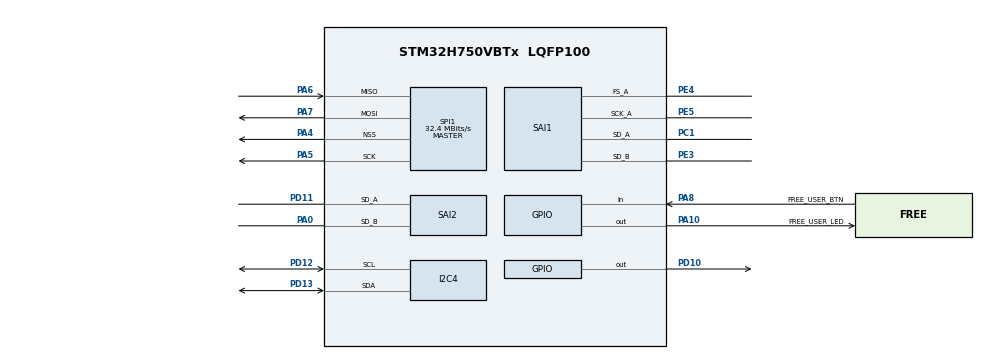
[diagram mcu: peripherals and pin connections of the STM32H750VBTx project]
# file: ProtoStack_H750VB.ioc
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CORTEX_M7.CPU_DCache=Disabled
CORTEX_M7.CPU_ICache=Enabled
CORTEX_M7.Enable-Cortex_Memory_Protection_Unit_Region0_Settings=__NULL
CORTEX_M7.Enable-Cortex_Memory_Protection_Unit_Region1_Settings=__NULL
CORTEX_M7.Enable-Cortex_Memory_Protection_Unit_Region2_Settings=__NULL
CORTEX_M7.MPU_Control=MPU_PRIVILEGED_DEFAULT
Dma.Request0=SAI1_A
Dma.Request1=SAI1_B
Dma.Request2=SAI2_A
Dma.Request3=SAI2_B
Dma.Request4=SPI1_RX
Dma.Request5=SPI1_TX
Dma.SAI1_A.0.Direction=DMA_PERIPH_TO_MEMORY
Dma.SAI1_A.0.EventEnable=DISABLE
Dma.SAI1_A.0.FIFOMode=DMA_FIFOMODE_DISABLE
Dma.SAI1_A.0.Instance=DMA1_Stream0
Dma.SAI1_A.0.MemDataAlignment=DMA_MDATAALIGN_HALFWORD
Dma.SAI1_A.0.MemInc=DMA_MINC_ENABLE
Dma.SAI1_A.0.Mode=DMA_CIRCULAR
Dma.SAI1_A.0.PeriphDataAlignment=DMA_PDATAALIGN_HALFWORD
Dma.SAI1_A.0.PeriphInc=DMA_PINC_DISABLE
Dma.SAI1_A.0.Polarity=HAL_DMAMUX_REQ_GEN_RISING
Dma.SAI1_A.0.Priority=DMA_PRIORITY_HIGH
Dma.SAI1_A.0.RequestNumber=1
Dma.SAI1_A.0.SignalID=NONE
Dma.SAI1_A.0.SyncEnable=DISABLE
Dma.SAI1_A.0.SyncPolarity=HAL_DMAMUX_SYNC_NO_EVENT
Dma.SAI1_A.0.SyncRequestNumber=1
Dma.SAI1_A.0.SyncSignalID=NONE
Dma.SAI1_B.1.Direction=DMA_MEMORY_TO_PERIPH
Dma.SAI1_B.1.EventEnable=DISABLE
Dma.SAI1_B.1.FIFOMode=DMA_FIFOMODE_DISABLE
Dma.SAI1_B.1.Instance=DMA1_Stream1
Dma.SAI1_B.1.MemDataAlignment=DMA_MDATAALIGN_HALFWORD
Dma.SAI1_B.1.MemInc=DMA_MINC_ENABLE
Dma.SAI1_B.1.Mode=DMA_CIRCULAR
Dma.SAI1_B.1.PeriphDataAlignment=DMA_PDATAALIGN_HALFWORD
Dma.SAI1_B.1.PeriphInc=DMA_PINC_DISABLE
Dma.SAI1_B.1.Polarity=HAL_DMAMUX_REQ_GEN_RISING
Dma.SAI1_B.1.Priority=DMA_PRIORITY_HIGH
Dma.SAI1_B.1.RequestNumber=1
Dma.SAI1_B.1.SignalID=NONE
Dma.SAI1_B.1.SyncEnable=DISABLE
Dma.SAI1_B.1.SyncPolarity=HAL_DMAMUX_SYNC_NO_EVENT
Dma.SAI1_B.1.SyncRequestNumber=1
Dma.SAI1_B.1.SyncSignalID=NONE
Dma.SAI2_A.2.Direction=DMA_PERIPH_TO_MEMORY
Dma.SAI2_A.2.EventEnable=DISABLE
Dma.SAI2_A.2.FIFOMode=DMA_FIFOMODE_DISABLE
Dma.SAI2_A.2.Instance=DMA1_Stream2
Dma.SAI2_A.2.MemDataAlignment=DMA_MDATAALIGN_HALFWORD
Dma.SAI2_A.2.MemInc=DMA_MINC_ENABLE
Dma.SAI2_A.2.Mode=DMA_CIRCULAR
Dma.SAI2_A.2.PeriphDataAlignment=DMA_PDATAALIGN_HALFWORD
Dma.SAI2_A.2.PeriphInc=DMA_PINC_DISABLE
Dma.SAI2_A.2.Polarity=HAL_DMAMUX_REQ_GEN_RISING
Dma.SAI2_A.2.Priority=DMA_PRIORITY_MEDIUM
Dma.SAI2_A.2.RequestNumber=1
Dma.SAI2_A.2.SignalID=NONE
Dma.SAI2_A.2.SyncEnable=DISABLE
Dma.SAI2_A.2.SyncPolarity=HAL_DMAMUX_SYNC_NO_EVENT
Dma.SAI2_A.2.SyncRequestNumber=1
Dma.SAI2_A.2.SyncSignalID=NONE
Dma.SAI2_B.3.Direction=DMA_MEMORY_TO_PERIPH
Dma.SAI2_B.3.EventEnable=DISABLE
Dma.SAI2_B.3.FIFOMode=DMA_FIFOMODE_DISABLE
Dma.SAI2_B.3.Instance=DMA1_Stream3
Dma.SAI2_B.3.MemDataAlignment=DMA_MDATAALIGN_HALFWORD
Dma.SAI2_B.3.MemInc=DMA_MINC_ENABLE
Dma.SAI2_B.3.Mode=DMA_CIRCULAR
Dma.SAI2_B.3.PeriphDataAlignment=DMA_PDATAALIGN_HALFWORD
Dma.SAI2_B.3.PeriphInc=DMA_PINC_DISABLE
Dma.SAI2_B.3.Polarity=HAL_DMAMUX_REQ_GEN_RISING
Dma.SAI2_B.3.Priority=DMA_PRIORITY_MEDIUM
Dma.SAI2_B.3.RequestNumber=1
Dma.SAI2_B.3.SignalID=NONE
Dma.SAI2_B.3.SyncEnable=DISABLE
Dma.SAI2_B.3.SyncPolarity=HAL_DMAMUX_SYNC_NO_EVENT
Dma.SAI2_B.3.SyncRequestNumber=1
Dma.SAI2_B.3.SyncSignalID=NONE
Dma.SPI1_RX.4.Direction=DMA_PERIPH_TO_MEMORY
Dma.SPI1_RX.4.EventEnable=DISABLE
Dma.SPI1_RX.4.FIFOMode=DMA_FIFOMODE_DISABLE
Dma.SPI1_RX.4.Instance=DMA1_Stream4
Dma.SPI1_RX.4.MemDataAlignment=DMA_MDATAALIGN_BYTE
Dma.SPI1_RX.4.MemInc=DMA_MINC_ENABLE
Dma.SPI1_RX.4.Mode=DMA_NORMAL
Dma.SPI1_RX.4.PeriphDataAlignment=DMA_PDATAALIGN_BYTE
Dma.SPI1_RX.4.PeriphInc=DMA_PINC_DISABLE
Dma.SPI1_RX.4.Polarity=HAL_DMAMUX_REQ_GEN_RISING
Dma.SPI1_RX.4.Priority=DMA_PRIORITY_LOW
Dma.SPI1_RX.4.RequestNumber=1
Dma.SPI1_RX.4.SignalID=NONE
Dma.SPI1_RX.4.SyncEnable=DISABLE
Dma.SPI1_RX.4.SyncPolarity=HAL_DMAMUX_SYNC_NO_EVENT
Dma.SPI1_RX.4.SyncRequestNumber=1
Dma.SPI1_RX.4.SyncSignalID=NONE
Dma.SPI1_TX.5.Direction=DMA_MEMORY_TO_PERIPH
Dma.SPI1_TX.5.EventEnable=DISABLE
Dma.SPI1_TX.5.FIFOMode=DMA_FIFOMODE_DISABLE
Dma.SPI1_TX.5.Instance=DMA1_Stream5
Dma.SPI1_TX.5.MemDataAlignment=DMA_MDATAALIGN_BYTE
Dma.SPI1_TX.5.MemInc=DMA_MINC_ENABLE
Dma.SPI1_TX.5.Mode=DMA_NORMAL
Dma.SPI1_TX.5.PeriphDataAlignment=DMA_PDATAALIGN_BYTE
Dma.SPI1_TX.5.PeriphInc=DMA_PINC_DISABLE
Dma.SPI1_TX.5.Polarity=HAL_DMAMUX_REQ_GEN_RISING
Dma.SPI1_TX.5.Priority=DMA_PRIORITY_LOW
Dma.SPI1_TX.5.RequestNumber=1
Dma.SPI1_TX.5.SignalID=NONE
Dma.SPI1_TX.5.SyncEnable=DISABLE
Dma.SPI1_TX.5.SyncPolarity=HAL_DMAMUX_SYNC_NO_EVENT
Dma.SPI1_TX.5.SyncRequestNumber=1
Dma.SPI1_TX.5.SyncSignalID=NONE
I2C4.Timing=0x307075B1
Mcu.Family=STM32H7
Mcu.Name=STM32H750VBTx
Mcu.Package=LQFP100
NVIC.DMA1_Stream0_IRQn=true\:0\:0\:false\:false\:true\:false\:true\:true
NVIC.DMA1_Stream1_IRQn=true\:0\:0\:false\:false\:true\:false\:true\:true
NVIC.DMA1_Stream2_IRQn=true\:0\:0\:false\:false\:true\:false\:true\:true
NVIC.DMA1_Stream3_IRQn=true\:0\:0\:false\:false\:true\:false\:true\:true
NVIC.DMA1_Stream4_IRQn=true\:0\:0\:false\:false\:true\:false\:true\:true
NVIC.DMA1_Stream5_IRQn=true\:0\:0\:false\:false\:true\:false\:true\:true
NVIC.PriorityGroup=NVIC_PRIORITYGROUP_4
NVIC.SAI1_IRQn=true\:0\:0\:false\:false\:true\:true\:true\:true
NVIC.SAI2_IRQn=true\:0\:0\:false\:false\:true\:true\:true\:true
NVIC.SPI1_IRQn=true\:0\:0\:false\:false\:true\:true\:true\:true
NVIC.TIM2_IRQn=true\:0\:0\:false\:false\:true\:true\:true\:true
PA0.Mode=SAI_B_SyncSlave
PA0.Signal=SAI2_SD_B
PA10.GPIO_Label=FREE_USER_LED
PA10.PinState=GPIO_PIN_SET
PA10.Signal=GPIO_Output
PA13\ (JTMS/SWDIO).Mode=Serial_Wire
PA13\ (JTMS/SWDIO).PinAttribute=Free
PA13\ (JTMS/SWDIO).Signal=DEBUG_JTMS-SWDIO
PA14\ (JTCK/SWCLK).Mode=Serial_Wire
PA14\ (JTCK/SWCLK).PinAttribute=Free
PA14\ (JTCK/SWCLK).Signal=DEBUG_JTCK-SWCLK
PA4.GPIO_PuPd=GPIO_PULLUP
PA4.GPIO_Speed=GPIO_SPEED_FREQ_VERY_HIGH
PA4.Mode=NSS_Signal_Hard_Output
PA4.Signal=SPI1_NSS
PA5.GPIO_Speed=GPIO_SPEED_FREQ_VERY_HIGH
PA5.Mode=Full_Duplex_Master
PA5.Signal=SPI1_SCK
PA6.GPIO_Speed=GPIO_SPEED_FREQ_VERY_HIGH
PA6.Mode=Full_Duplex_Master
PA6.Signal=SPI1_MISO
PA7.GPIO_Speed=GPIO_SPEED_FREQ_VERY_HIGH
PA7.Mode=Full_Duplex_Master
PA7.Signal=SPI1_MOSI
PA8.GPIO_Label=FREE_USER_BTN
PA8.PinAttribute=Free
PA8.Signal=GPIO_Input
PC1.Mode=SAI_A_AsyncSlave
PC1.PinAttribute=Free
PC1.Signal=SAI1_SD_A
PD10.Signal=GPIO_Output
PD11.Mode=SAI_A_SyncSlave
PD11.Signal=SAI2_SD_A
PD12.Mode=I2C
PD12.Signal=I2C4_SCL
PD13.Mode=I2C
PD13.Signal=I2C4_SDA
PE3.Mode=SAI_B_SyncSlave
PE3.PinAttribute=Free
PE3.Signal=SAI1_SD_B
PE4.Mode=SAI_A_AsyncSlave
PE4.Signal=SAI1_FS_A
PE5.GPIO_Speed=GPIO_SPEED_FREQ_LOW
PE5.Mode=SAI_A_AsyncSlave
PE5.Signal=SAI1_SCK_A
PH0-OSC_IN\ (PH0).Mode=HSE-External-Oscillator
PH0-OSC_IN\ (PH0).PinAttribute=Free
PH0-OSC_IN\ (PH0).Signal=RCC_OSC_IN
PH1-OSC_OUT\ (PH1).Mode=HSE-External-Oscillator
PH1-OSC_OUT\ (PH1).PinAttribute=Free
PH1-OSC_OUT\ (PH1).Signal=RCC_OSC_OUT
ProjectManager.HeapSize=0x200
ProjectManager.StackSize=0x400
ProjectManager.TargetToolchain=STM32CubeIDE
RCC.ADCCLockSelection=RCC_ADCCLKSOURCE_PLL2
RCC.ADCFreq_Value=129600000
RCC.APB1Freq_Value=120000000
RCC.APB2Freq_Value=120000000
RCC.APB3Freq_Value=120000000
RCC.APB4Freq_Value=120000000
RCC.CECCLockSelection=RCC_CECCLKSOURCE_LSI
RCC.CKPERSourceSelection=RCC_CLKPSOURCE_HSI
RCC.CSI_VALUE=4000000
RCC.CortexFreq_Value=60000000
RCC.Cortex_Div=SYSTICK_CLKSOURCE_HCLK_DIV8
RCC.Cortex_DivARG=SystemCoreClock/1000
RCC.D1PPRE=RCC_APB3_DIV2
RCC.D2PPRE1=RCC_APB1_DIV2
RCC.D2PPRE2=RCC_APB2_DIV2
RCC.D3PPRE=RCC_APB4_DIV2
RCC.DFSDMCLockSelection=RCC_DFSDM1CLKSOURCE_D2PCLK1
RCC.DIVM1=4
RCC.DIVM2=4
RCC.DIVM3=10
RCC.DIVN1=160
RCC.DIVN2=108
RCC.DIVN3=128
RCC.DIVP2=5
RCC.DIVP3=25
RCC.DIVQ1=20
RCC.DIVQ2=2
RCC.DIVQ3=16
RCC.DIVR1=10
RCC.DIVR2=3
RCC.DSICLockSelection=RCC_DSICLKSOURCE_PHY
RCC.DSIPHY_Div=8
RCC.DSITX_Div=4
RCC.DSI_PHY_VALUE=12288000
RCC.EXTERNAL_CLOCK_VALUE=12288000
RCC.EnbaleCSS=true
RCC.FDCANCLockSelection=RCC_FDCANCLKSOURCE_PLL
RCC.HCLKFreq_Value=240000000
RCC.HPRE=RCC_HCLK_DIV2
RCC.HSE_VALUE=24000000
RCC.HSIDiv=RCC_PLLSAIDIVR_4
RCC.HSI_VALUE=64000000
RCC.I2C123CLockSelection=RCC_I2C123CLKSOURCE_D2PCLK1
RCC.I2C4CLockSelection=RCC_I2C4CLKSOURCE_D3PCLK1
RCC.LPTIM1CLockSelection=RCC_LPTIM1CLKSOURCE_D2PCLK1
RCC.LPTIM2CLockSelection=RCC_LPTIM2CLKSOURCE_D3PCLK1
RCC.LPTIM345CLockSelection=RCC_LPTIM345CLKSOURCE_D3PCLK1
RCC.LPUART1CLockSelection=RCC_LPUART1CLKSOURCE_D3PCLK1
RCC.LSEState=RCC_LSE_OFF
RCC.LSE_VALUE=32768
RCC.PLL1_VCI_Range-AdvancedSettings=RCC_PLL1VCIRANGE_0
RCC.PLLDSIDev=2
RCC.PLLDSIIDF=DSI_PLL_IN_DIV1
RCC.PLLDSIMult=2
RCC.PLLDSINDIV=20
RCC.PLLDSIODF=DSI_PLL_OUT_DIV1
RCC.PLLFRACN=0
RCC.PLLSourceVirtual=RCC_PLLSOURCE_HSE
RCC.QSPICLockSelection=RCC_QSPICLKSOURCE_PLL2
RCC.RC48_VALUE=48000000
RCC.RCC_MCO1Source=RCC_MCO1SOURCE_HSI
RCC.RCC_MCO2Source=RCC_MCO2SOURCE_SYSCLK
RCC.RCC_MCODiv1=RCC_MCODIV_1
RCC.RCC_MCODiv2=RCC_MCODIV_1
RCC.RCC_RTC_Clock_Source_FROM_HSE=RCC_RTCCLKSOURCE_HSE_DIV2
RCC.RNGCLockSelection=RCC_RNGCLKSOURCE_HSI48
RCC.SAI1CLockSelection=RCC_SAI1CLKSOURCE_PLL3
RCC.SAI23CLockSelection=RCC_SAI23CLKSOURCE_PLL3
RCC.SAI4ACLockSelection=RCC_SAI4ACLKSOURCE_PLL
RCC.SAI4BCLockSelection=RCC_SAI4BCLKSOURCE_PLL
RCC.SPDIFCLockSelection=RCC_SPDIFRXCLKSOURCE_PLL
RCC.SPI123CLockSelection=RCC_SPI123CLKSOURCE_PLL2
RCC.SPI6CLockSelection=RCC_SPI6CLKSOURCE_PLL3
RCC.SWPCLockSelection=RCC_SWPMI1CLKSOURCE_D2PCLK1
RCC.SYSCLKFreq_VALUE=480000000
RCC.SYSCLKSource=RCC_SYSCLKSOURCE_PLLCLK
RCC.Spi45ClockSelection=RCC_SPI45CLKSOURCE_D2PCLK1
RCC.USART16CLockSelection=RCC_USART16CLKSOURCE_D2PCLK2
RCC.USART234578CLockSelection=RCC_USART234578CLKSOURCE_D2PCLK1
RCC.USBCLockSelection=RCC_USBCLKSOURCE_HSI48
RCC.USBFreq_Value=48000000
SAI1.AudioMode-SAI_B_SyncSlave=SAI_MODESLAVE_TX
SAI1.BasicDataSize-SAI_A_AsyncSlave=SAI_PROTOCOL_DATASIZE_16BITEXTENDED
SAI1.BasicDataSize-SAI_B_SyncSlave=SAI_PROTOCOL_DATASIZE_16BITEXTENDED
SAI1.FIFOThreshold-SAI_B_SyncSlave=SAI_FIFOTHRESHOLD_EMPTY
SAI1.InitProtocol-SAI_A_AsyncSlave=Enable
SAI1.InitProtocol-SAI_B_SyncSlave=Enable
SAI1.Instance-SAI_A_AsyncSlave=SAI$Index_Block_A
SAI1.Instance-SAI_B_SyncSlave=SAI$Index_Block_B
SAI1.SynchroExt=SAI_SYNCEXT_OUTBLOCKA_ENABLE
SAI1.Synchro_A=SAI_ASYNCHRONOUS
SAI1.Synchro_B=SAI_SYNCHRONOUS
SAI1.VirtualMode-SAI_A_AsyncSlave=VM_SLAVE
SAI1.VirtualMode-SAI_B_SyncSlave=VM_SLAVE
SAI1.VirtualProtocol-SAI_A_BASIC=VM_BASIC_PROTOCOL
SAI1.VirtualProtocol-SAI_B_BASIC=VM_BASIC_PROTOCOL
SAI2.AudioMode-SAI_B_SyncSlave=SAI_MODESLAVE_TX
SAI2.BasicDataSize-SAI_A_SyncSlave=SAI_PROTOCOL_DATASIZE_16BITEXTENDED
SAI2.BasicDataSize-SAI_B_SyncSlave=SAI_PROTOCOL_DATASIZE_16BITEXTENDED
SAI2.FIFOThreshold-SAI_B_SyncSlave=SAI_FIFOTHRESHOLD_EMPTY
SAI2.InitProtocol-SAI_A_SyncSlave=Enable
SAI2.InitProtocol-SAI_B_SyncSlave=Enable
SAI2.Instance-SAI_A_SyncSlave=SAI$Index_Block_A
SAI2.Instance-SAI_B_SyncSlave=SAI$Index_Block_B
SAI2.Synchro_A=SAI_SYNCHRONOUS_EXT_SAI1
SAI2.Synchro_B=SAI_SYNCHRONOUS
SAI2.VirtualMode-SAI_A_SyncSlave=VM_SLAVE
SAI2.VirtualMode-SAI_B_SyncSlave=VM_SLAVE
SAI2.VirtualProtocol-SAI_A_BASIC=VM_BASIC_PROTOCOL
SAI2.VirtualProtocol-SAI_B_BASIC=VM_BASIC_PROTOCOL
SPI1.BaudRatePrescaler=SPI_BAUDRATEPRESCALER_4
SPI1.CalculateBaudRate=32.4 MBits/s
SPI1.DataSize=SPI_DATASIZE_16BIT
SPI1.Direction=SPI_DIRECTION_2LINES
SPI1.MasterSSIdleness=SPI_MASTER_SS_IDLENESS_00CYCLE
SPI1.Mode=SPI_MODE_MASTER
SPI1.NSSPMode=SPI_NSS_PULSE_ENABLE
SPI1.VirtualNSS=VM_NSSHARD
SPI1.VirtualType=VM_MASTER
TIM2.ClockDivision=TIM_CLOCKDIVISION_DIV4
TIM2.CounterMode=TIM_COUNTERMODE_DOWN
TIM2.Period=139999999
VP_CRC_VS_CRC.Mode=CRC_Activate
VP_RNG_VS_RNG.Mode=RNG_Activate
VP_SAI1_VP_$IpInstance_SAIA_SAI_BASIC.Mode=SAI_A_BASIC
VP_SAI1_VP_$IpInstance_SAIB_SAI_BASIC.Mode=SAI_B_BASIC
VP_SAI1_VP_$IpInstance_SYNCHRO_EXTERNAL.Mode=SynchroExternal
VP_SAI2_VP_$IpInstance_SAIA_SAI_BASIC.Mode=SAI_A_BASIC
VP_SAI2_VP_$IpInstance_SAIB_SAI_BASIC.Mode=SAI_B_BASIC
VP_TIM2_VS_ClockSourceINT.Mode=Internal
board=custom

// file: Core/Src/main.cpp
/* USER CODE BEGIN Header */
/**
  ******************************************************************************
  * @file           : main.c
  * @brief          : Main program body
  ******************************************************************************
  * @attention
  *
  * Copyright (c) 2022 STMicroelectronics.
  * All rights reserved.
  *
  * This software is licensed under terms that can be found in the LICENSE file
  * in the root directory of this software component.
  * If no LICENSE file comes with this software, it is provided AS-IS.
  *
  ******************************************************************************
  */
/* USER CODE END Header */
#include "main.h"
#include "crc.h"
#include "dma.h"
#include "i2c.h"
#include "rng.h"
#include "sai.h"
#include "spi.h"
#include "tim.h"
#include "gpio.h"

/* USER CODE BEGIN Includes */

///////////////////////////////////////////////////////////////////
// write manually init SAI1 after DMA - function call in cube is disabled (wrong order generation)
// first enable codec1 (slave), then codec0 (master)
// disable d-cache to ensure correct data transfers (particulary DMA)
// check that MAX_MODULES_NUM is correct
//
//__attribute__ ((section(".ramd"), used))
///////////////////////////////////////////////////////////////////
#include <stdio.h>
#include <string.h>

#include "Handy.h"
#include "../../Drivers/HW/wm8731.h"
#include "../../Drivers/HW/LY68L6400.h"
#include "../../Modules/AudioSysObjects.hpp"

/* USER CODE END Includes */

void SystemClock_Config(void);
void PeriphCommonClock_Config(void);
static void MPU_Config(void);

int main(void)
{

  /* MPU Configuration--------------------------------------------------------*/
  MPU_Config();

  /* Enable I-Cache---------------------------------------------------------*/
  SCB_EnableICache();

  /* MCU Configuration--------------------------------------------------------*/

  /* Reset of all peripherals, Initializes the Flash interface and the Systick. */
  HAL_Init();

  /* Configure the system clock */
  SystemClock_Config();

/* Configure the peripherals common clocks */
  PeriphCommonClock_Config();

  /* Initialize all configured peripherals */
  MX_GPIO_Init();
  MX_DMA_Init();
  MX_CRC_Init();
  MX_SAI2_Init();
  MX_SAI1_Init();
  MX_RNG_Init();
  MX_TIM2_Init();
  MX_I2C4_Init();
  MX_SPI1_Init();
  /* USER CODE BEGIN 2 */

	CodecPowerUp(CODEC_ADDRESS_1);
	SetHPGain(-8,CODEC_ADDRESS_1);

	CodecPowerUp(CODEC_ADDRESS_0);
	SetHPGain(-8,CODEC_ADDRESS_0);

	saiAdapter_Init(&sai2adapter,HW_SAI2);
	saiAdapter_Init(&sai1adapter,HW_SAI1);

//uint16_t a[256];
//for(uint16_t i = 0; i < 256; i++)
//	a[i] = i;
//
//PsramWrite(a, 256,0);
//uint16_t rxbuf[256 + 2];
//PsramRead(rxbuf, 256,0);
//HAL_Delay(1);

	audioSystem.includeModules();

////////////////////////////////////////////
  /* USER CODE END 2 */

  /* Infinite loop */
  /* USER CODE BEGIN WHILE */
  while (1)
  {

	  audioSystem.update();
//		HAL_GPIO_TogglePin(FREE_USER_LED_GPIO_Port, FREE_USER_LED_Pin);

    /* USER CODE END WHILE */

  }
}

void SystemClock_Config(void)
{
  RCC_OscInitTypeDef RCC_OscInitStruct = {0};
  RCC_ClkInitTypeDef RCC_ClkInitStruct = {0};

  /** Supply configuration update enable
  */
  HAL_PWREx_ConfigSupply(PWR_LDO_SUPPLY);

  /** Configure the main internal regulator output voltage
  */
  __HAL_PWR_VOLTAGESCALING_CONFIG(PWR_REGULATOR_VOLTAGE_SCALE0);

  while(!__HAL_PWR_GET_FLAG(PWR_FLAG_VOSRDY)) {}

  /** Macro to configure the PLL clock source
  */
  __HAL_RCC_PLL_PLLSOURCE_CONFIG(RCC_PLLSOURCE_HSE);

  /** Initializes the RCC Oscillators according to the specified parameters
  * in the RCC_OscInitTypeDef structure.
  */
  RCC_OscInitStruct.OscillatorType = RCC_OSCILLATORTYPE_HSI48|RCC_OSCILLATORTYPE_HSE;
  RCC_OscInitStruct.HSEState = RCC_HSE_ON;
  RCC_OscInitStruct.HSI48State = RCC_HSI48_ON;
  RCC_OscInitStruct.PLL.PLLState = RCC_PLL_ON;
  RCC_OscInitStruct.PLL.PLLSource = RCC_PLLSOURCE_HSE;
  RCC_OscInitStruct.PLL.PLLM = 4;
  RCC_OscInitStruct.PLL.PLLN = 160;
  RCC_OscInitStruct.PLL.PLLP = 2;
  RCC_OscInitStruct.PLL.PLLQ = 20;
  RCC_OscInitStruct.PLL.PLLR = 10;
  RCC_OscInitStruct.PLL.PLLRGE = RCC_PLL1VCIRANGE_2;
  RCC_OscInitStruct.PLL.PLLVCOSEL = RCC_PLL1VCOWIDE;
  RCC_OscInitStruct.PLL.PLLFRACN = 0;
  if (HAL_RCC_OscConfig(&RCC_OscInitStruct) != HAL_OK)
  {
    Error_Handler();
  }

  /** Initializes the CPU, AHB and APB buses clocks
  */
  RCC_ClkInitStruct.ClockType = RCC_CLOCKTYPE_HCLK|RCC_CLOCKTYPE_SYSCLK
                              |RCC_CLOCKTYPE_PCLK1|RCC_CLOCKTYPE_PCLK2
                              |RCC_CLOCKTYPE_D3PCLK1|RCC_CLOCKTYPE_D1PCLK1;
  RCC_ClkInitStruct.SYSCLKSource = RCC_SYSCLKSOURCE_PLLCLK;
  RCC_ClkInitStruct.SYSCLKDivider = RCC_SYSCLK_DIV1;
  RCC_ClkInitStruct.AHBCLKDivider = RCC_HCLK_DIV2;
  RCC_ClkInitStruct.APB3CLKDivider = RCC_APB3_DIV2;
  RCC_ClkInitStruct.APB1CLKDivider = RCC_APB1_DIV2;
  RCC_ClkInitStruct.APB2CLKDivider = RCC_APB2_DIV2;
  RCC_ClkInitStruct.APB4CLKDivider = RCC_APB4_DIV2;

  if (HAL_RCC_ClockConfig(&RCC_ClkInitStruct, FLASH_LATENCY_4) != HAL_OK)
  {
    Error_Handler();
  }

  /** Enables the Clock Security System
  */
  HAL_RCC_EnableCSS();
}

void PeriphCommonClock_Config(void)
{
  RCC_PeriphCLKInitTypeDef PeriphClkInitStruct = {0};

  /** Initializes the peripherals clock
  */
  PeriphClkInitStruct.PeriphClockSelection = RCC_PERIPHCLK_SAI1|RCC_PERIPHCLK_SAI2;
  PeriphClkInitStruct.PLL3.PLL3M = 10;
  PeriphClkInitStruct.PLL3.PLL3N = 128;
  PeriphClkInitStruct.PLL3.PLL3P = 25;
  PeriphClkInitStruct.PLL3.PLL3Q = 16;
  PeriphClkInitStruct.PLL3.PLL3R = 2;
  PeriphClkInitStruct.PLL3.PLL3RGE = RCC_PLL3VCIRANGE_1;
  PeriphClkInitStruct.PLL3.PLL3VCOSEL = RCC_PLL3VCOWIDE;
  PeriphClkInitStruct.PLL3.PLL3FRACN = 0;
  PeriphClkInitStruct.Sai1ClockSelection = RCC_SAI1CLKSOURCE_PLL3;
  PeriphClkInitStruct.Sai23ClockSelection = RCC_SAI23CLKSOURCE_PLL3;
  if (HAL_RCCEx_PeriphCLKConfig(&PeriphClkInitStruct) != HAL_OK)
  {
    Error_Handler();
  }
}

/* MPU Configuration */

void MPU_Config(void)
{

  /* Disables the MPU */
  HAL_MPU_Disable();
  /* Enables the MPU */
  HAL_MPU_Enable(MPU_PRIVILEGED_DEFAULT);

}

void Error_Handler(void)
{
  __disable_irq();
  while (1)
  {
  }
}
